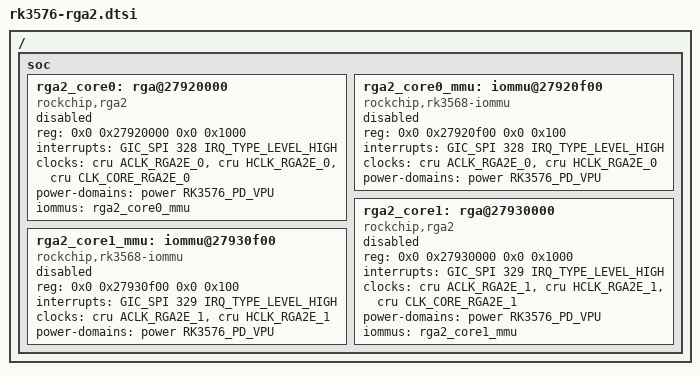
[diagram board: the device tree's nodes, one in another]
// SPDX-License-Identifier: (GPL-2.0-only OR MIT)
/*
 * RK3576 RGA2E 双核节点，供 rk3576.dtsi 使用（rockchip-rga3 驱动）。
 * IOMMU 采用主线 rockchip,rk3568-iommu，与 rkjpegd 的用法一致。
 */

/ {
	soc {
		rga2_core0: rga@27920000 {
			compatible = "rockchip,rga2";
			reg = <0x0 0x27920000 0x0 0x1000>;
			interrupts = <GIC_SPI 328 IRQ_TYPE_LEVEL_HIGH>;
			interrupt-names = "rga2_core0_irq";
			clocks = <&cru ACLK_RGA2E_0>, <&cru HCLK_RGA2E_0>, <&cru CLK_CORE_RGA2E_0>;
			clock-names = "aclk_rga", "hclk_rga", "clk_rga";
			power-domains = <&power RK3576_PD_VPU>;
			iommus = <&rga2_core0_mmu>;
			status = "disabled";
		};

		rga2_core0_mmu: iommu@27920f00 {
			compatible = "rockchip,rk3568-iommu";
			reg = <0x0 0x27920f00 0x0 0x100>;
			interrupts = <GIC_SPI 328 IRQ_TYPE_LEVEL_HIGH>;
			interrupt-names = "rga2_0_mmu";
			clocks = <&cru ACLK_RGA2E_0>, <&cru HCLK_RGA2E_0>;
			clock-names = "aclk", "iface";
			power-domains = <&power RK3576_PD_VPU>;
			#iommu-cells = <0>;
			status = "disabled";
		};

		rga2_core1: rga@27930000 {
			compatible = "rockchip,rga2";
			reg = <0x0 0x27930000 0x0 0x1000>;
			interrupts = <GIC_SPI 329 IRQ_TYPE_LEVEL_HIGH>;
			interrupt-names = "rga2_core1_irq";
			clocks = <&cru ACLK_RGA2E_1>, <&cru HCLK_RGA2E_1>, <&cru CLK_CORE_RGA2E_1>;
			clock-names = "aclk_rga", "hclk_rga", "clk_rga";
			power-domains = <&power RK3576_PD_VPU>;
			iommus = <&rga2_core1_mmu>;
			status = "disabled";
		};

		rga2_core1_mmu: iommu@27930f00 {
			compatible = "rockchip,rk3568-iommu";
			reg = <0x0 0x27930f00 0x0 0x100>;
			interrupts = <GIC_SPI 329 IRQ_TYPE_LEVEL_HIGH>;
			interrupt-names = "rga2_1_mmu";
			clocks = <&cru ACLK_RGA2E_1>, <&cru HCLK_RGA2E_1>;
			clock-names = "aclk", "iface";
			power-domains = <&power RK3576_PD_VPU>;
			#iommu-cells = <0>;
			status = "disabled";
		};
	};
};
